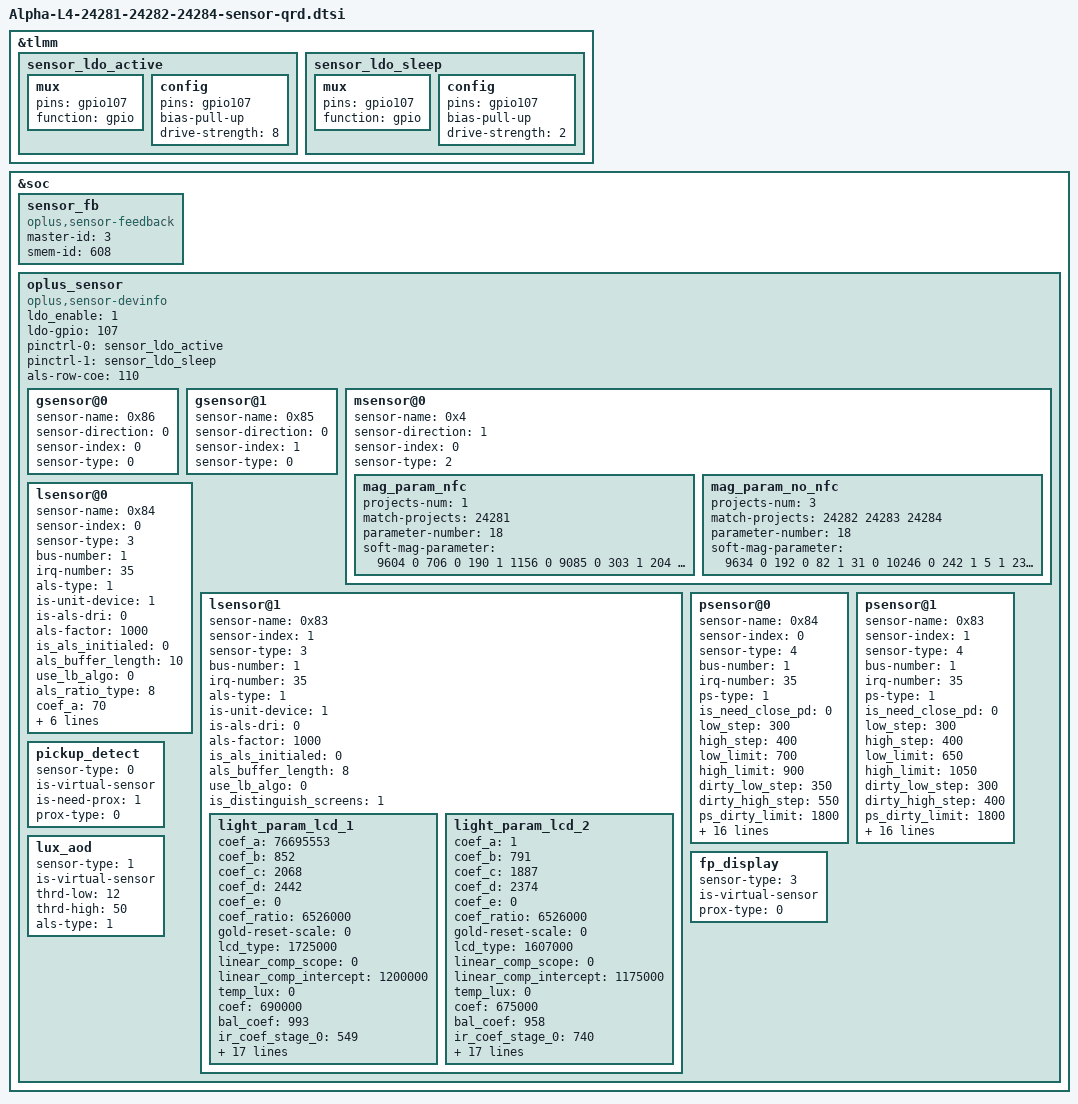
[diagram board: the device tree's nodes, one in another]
&tlmm {
	sensor_ldo_active: sensor_ldo_active {
		mux {
			pins = "gpio107";
			function = "gpio";
		};
		config {
			pins = "gpio107";
			bias-pull-up;
			drive-strength = <8>;
		};
	};
	sensor_ldo_sleep: sensor_ldo_sleep {
		mux {
			pins = "gpio107";
			function = "gpio";
		};
		config {
			pins = "gpio107";
			bias-pull-up;
			drive-strength = <2>;
		};
	};
};

&soc {
	sensor_fb: sensor_fb {
		compatible = "oplus,sensor-feedback";
		master-id  = <3>;
		smem-id    = <608>;
	};
	oplus_sensor {
			compatible = "oplus,sensor-devinfo";

			ldo_enable = <1>;
			ldo-gpio = <107>;
			pinctrl-names = "sensor_ldo_active", "sensor_ldo_sleep";
			pinctrl-0 = <&sensor_ldo_active>;
			pinctrl-1 = <&sensor_ldo_sleep>;

			als-row-coe = <110>;
			/*enum {LSM6DSM = 0x01, BMI160 = 0x02, LSM6DS3 = 0x04, BMI260 = 0x08};*/
			gsensor@0 {
					sensor-name = <0x86>;//STK83xx
					sensor-direction = <0>;
					sensor-index = <0>;//source num
					sensor-type = <0>;//OPPO_ACCEL
			};
			gsensor@1 {
					sensor-name = <0x85>;//SC7A20
					sensor-direction = <0>;
					sensor-index = <1>;//source num
					sensor-type = <0>;//OPPO_ACCEL
			};
			/* enum {AKM0991X = 0x01, MMC5603 = 0x02, MXG4300 = 0x04};*/
			msensor@0 {
				sensor-name = <0x4>;//MXG4300
				sensor-direction = <1>;
				sensor-index = <0>;
				sensor-type = <2>;//OPLUS_MAG
				mag_param_nfc {
					projects-num = <1>;
					match-projects = <24281>;
					parameter-number= <18>;
					soft-mag-parameter = <9604 0 706 0 190 1 1156 0 9085 0 303 1 204 0 245 1 10668 0>;//e00 sign e01 sign...
				};
				mag_param_no_nfc {
					projects-num = <3>;
					match-projects = <24282 24283 24284>;
					parameter-number= <18>;
					soft-mag-parameter = <9634 0 192 0 82 1 31 0 10246 0 242 1 5 1 230 0 10702 0>;//e00 sign e01 sign...
				};
			};
			/*enum {STK3A5X=0x01,TCS3701=0x02,TCS3408=0x04,STK326X=0x08,MN78911=0x10};*/
			/*enum {NORMAL=0x01,UNDER_LCD=0x02,VIRTUAL_UNDER_LCD=0x03}*/
			lsensor@0 {
					sensor-name = <0x84>;//STK6A7X
					sensor-index = <0>;
					sensor-type = <3>;//OPLUS_ALS
					bus-number = <1>;
					irq-number = <35>;
					als-type = <1>;//NORMAL_LCD
					is-unit-device = <1>;
					is-als-dri = <0>;
					als-factor = <1000>;
					is_als_initialed = <0>;
					als_buffer_length = <10>;
					use_lb_algo = <0>;
					als_ratio_type = <8>;
					coef_a     = <70>;//for A
					coef_b     = <38>;//for HZ
					coef_c     = <280>;//for CWF
					coef_d     = <82>;//for D65
					coef_e     = <156>;//for SUN
					coef_ratio = <13000>;
					lcd_name = "P_4";
			};
			lsensor@1 {
					sensor-name = <0x83>;//SIP3511
					sensor-index = <1>;
					sensor-type = <3>;//OPLUS_ALS
					bus-number = <1>;
					irq-number = <35>;
					als-type = <1>;//NORMAL_LCD
					is-unit-device = <1>;
					is-als-dri = <0>;
					als-factor = <1000>;
					is_als_initialed = <0>;
					als_buffer_length = <8>;
					//normalization_value = <549>;
					use_lb_algo = <0>;
					is_distinguish_screens = <1>;
				light_param_lcd_1 {
					coef_a     = <76695553>;
					coef_b     = <852>;
					coef_c     = <2068>;
					coef_d     = <2442>;
					coef_e     = <0>;
					coef_ratio = <6526000>;
					gold-reset-scale = <0>;
					lcd_type = <1725000>;
					linear_comp_scope = <0>;
					linear_comp_intercept = <1200000>;
					temp_lux = <0>;
					coef = <690000>;
					bal_coef = <993>;
					ir_coef_stage_0 = <549>;
					ir_coef_stage_1 = <4>;
					ir_coef_stage_2 = <1038>;
					ir_coef_stage_3 = <674>;
					ir_coef_val_0 = <17>;
					ir_coef_val_1 = <1011>;
					ir_coef_val_2 = <615>;
					ir_coef_val_3 = <3>;
					ir_coef_val_4 = <1048>;
					polling_use_majority = <738>;
					k43 = <15>;
					k51 = <984>;
					k52 = <516>;
					k53 = <5>;
					k61 = <1034>;
					k62 = <642>;
					k63 = <18>;
					lcd_name = "ili9883c";//主供boe
				};
				light_param_lcd_2 {
					coef_a     = <1>;
					coef_b     = <791>;
					coef_c     = <1887>;
					coef_d     = <2374>;
					coef_e     = <0>;
					coef_ratio = <6526000>;
					gold-reset-scale = <0>;
					lcd_type = <1607000>;
					linear_comp_scope = <0>;
					linear_comp_intercept = <1175000>;
					temp_lux = <0>;
					coef = <675000>;
					bal_coef = <958>;
					ir_coef_stage_0 = <740>;
					ir_coef_stage_1 = <25>;
					ir_coef_stage_2 = <964>;
					ir_coef_stage_3 = <817>;
					ir_coef_val_0 = <49>;
					ir_coef_val_1 = <965>;
					ir_coef_val_2 = <810>;
					ir_coef_val_3 = <21>;
					ir_coef_val_4 = <972>;
					polling_use_majority = <911>;
					k43 = <42>;
					k51 = <954>;
					k52 = <704>;
					k53 = <27>;
					k61 = <959>;
					k62 = <769>;
					k63 = <52>;
					lcd_name = "td4160";//二供hx
				};
			};
			psensor@0 {
					sensor-name = <0x84>;//STK6A7X
					sensor-index = <0>;
					sensor-type = <4>;//OPLUS_PROXIMITY
					bus-number = <1>;
					irq-number = <35>;
					//ps-cail-type = <2>;
					ps-type = <1>;
					/*1-need close 2-close has contidition 0-not close*/
					is_need_close_pd = <0>;
					//is_ps_initialzed = <0>;
					low_step = <300>;
					high_step = <400>;
					low_limit = <700>;
					high_limit = <900>;
					dirty_low_step = <350>;
					dirty_high_step = <550>;
					ps_dirty_limit = <1800>;
					ps_ir_limit = <2000>;
					ps_adjust_min = <0>;
					ps_adjust_max = <1850>;
					sampling_count = <5>;
					step_max = <400>;
					step_min = <100>;
					step_div = <2000>;
					anti_shake_delta = <70>;
					dynamic_cali_max = <5000>;
					raw2offset_radio = <1000>;
					offset_max = <60000>;
					offset_range_min = <0>;
					offset_range_max = <65535>;
					force_cali_limit = <2000>;
					cali_jitter_limit = <30>;
					cal_offset_margin = <3000>;
			};
			psensor@1 {
					sensor-name = <0x83>;//SIP3511
					sensor-index = <1>;
					sensor-type = <4>;//OPLUS_PROXIMITY
					bus-number = <1>;
					irq-number = <35>;
					//ps-cail-type = <2>;
					ps-type = <1>;
					/*1-need close 2-close has contidition 0-not close*/
					is_need_close_pd = <0>;
					//is_ps_initialzed = <0>;
					low_step = <300>;
					high_step = <400>;
					low_limit = <650>;
					high_limit = <1050>;
					dirty_low_step = <300>;
					dirty_high_step = <400>;
					ps_dirty_limit = <1800>;
					ps_ir_limit = <2000>;
					ps_adjust_min = <0>;
					ps_adjust_max = <1850>;
					sampling_count = <5>;
					step_max = <400>;
					step_min = <100>;
					step_div = <2000>;
					anti_shake_delta = <70>;
					dynamic_cali_max = <2000>;
					raw2offset_radio = <1000>;
					offset_max = <60000>;
					offset_range_min = <0>;
					offset_range_max = <65534>;
					force_cali_limit = <2000>;
					cali_jitter_limit = <30>;
					cal_offset_margin = <3000>;
			};
			/*
			cctrsensor@0 {
				decoupled-driver = <1>; //0 - tcs3408 driver; 1 - oplus_cct driver
				sensor-name = <0x10>; //sip1221lr1n
				sensor-index = <0>;
				sensor-type = <7>; //OPLUS_CCT_REAR
				bus-number = <1>;
				//feature
				publish-sensors = <0x5>; //bit[0] - als, bit[1] - rgb, bit[2] - flicker, bit[3] - spectral
				is-ch-dri = <0>;
				timer-size = <25>; //ms
				fac-cali-sensor = <0x1>; //0x1 - als, 0x2 - rgb, 0x4, flicker
				para-matrix = <0>;//0-default
			};*/

			/*virtual sensor
			enum sensor_algo_id {
					OPLUS_PICKUP_DETECT,
					OPLUS_LUX_AOD,
					OPLUS_TP_GESTURE,
					OPLUS_FP_DISPLAY,
					OPLUS_FREE_FALL,
					OPLUS_CAMERA_PROTECT,
					SENSOR_ALGO_NUM
			}*/
			pickup_detect {
					sensor-type = <0>; //OPLUS_PICKUP_DETECT
					is-virtual-sensor;
					is-need-prox = <1>;
					prox-type = <0>; // 0 - proximity; 1 - proximity_fake
			};
			lux_aod {
					sensor-type = <1>; //OPLUS_LUX_AOD
					is-virtual-sensor;
					thrd-low = <12>;
					thrd-high = <50>;
					als-type = <1>; // 0 - wise_light; 1 - ambient_light
			};
			fp_display {
					sensor-type = <3>; //OPLUS_FP_DISPLAY
					is-virtual-sensor;
					prox-type = <0>; // 0 - proximity; 1 - proximity_fake
			};
	};
};
